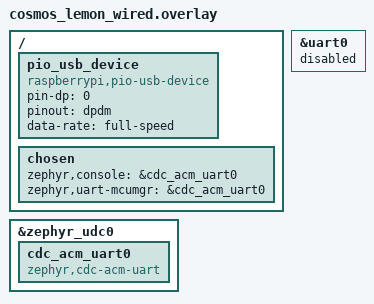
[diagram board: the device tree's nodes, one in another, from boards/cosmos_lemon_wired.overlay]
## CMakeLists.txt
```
# SPDX-License-Identifier: MIT

cmake_minimum_required(VERSION 3.20.0)
find_package(Zephyr REQUIRED HINTS $ENV{ZEPHYR_BASE})
project(pio_usb_device)

target_sources(app PRIVATE src/main.c)
```

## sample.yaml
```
sample:
  name: Pico-PIO-USB UDC standalone
  description: |
    Brings up udc_pio_usb on a Lemon Wired and exposes a CDC ACM device
    on the configured Link USB-C port. Pair with samples/pio_usb_host/
    on a second Lemon for an end-to-end test.
tests:
  sample.zephyr-module-pio-usb.device:
    platform_allow: cosmos_lemon_wired rpi_pico
    tags: usb pio
```

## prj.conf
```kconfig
# SPDX-License-Identifier: MIT
#
# Pico-PIO-USB device standalone sample. Brings up udc_pio_usb on a
# Lemon Wired and exposes a CDC ACM device on the configured Link
# USB-C port via Zephyr's USBD-next stack.
#
# Logs go out the native USB-C port via a separate CDC ACM instance.
# The CDC ACM that the Link port presents is the test endpoint — type
# in the host's tty and it should echo back.

CONFIG_MAIN_STACK_SIZE=2048

CONFIG_LOG=y
CONFIG_LOG_BUFFER_SIZE=8192
CONFIG_LOG_DEFAULT_LEVEL=3
CONFIG_LOG_PRINTK=y
CONFIG_LOG_MODE_IMMEDIATE=y
CONFIG_USB_DRIVER_LOG_LEVEL_INF=y
CONFIG_UDC_DRIVER_LOG_LEVEL_DBG=y
CONFIG_USB_DEVICE_LOG_LEVEL_INF=y

# udc_pio_usb on the Link USB-C port (PIO-driven).
CONFIG_UDC_DRIVER=y
CONFIG_UDC_PIO_USB=y
CONFIG_DYNAMIC_INTERRUPTS=y

# Legacy USB device stack on the native USB-C port for serial console
# only — no USBD-next on Link. Once udc_pio_usb is hardware-validated,
# add USBD-next + CDC ACM back to expose a real CDC ACM device on Link.
# Both stacks can't define CDC ACM concurrently (linker conflict on
# duplicated DT instance ordinals), so this triage build trades the
# Link-side test endpoint for a native serial console.
CONFIG_USB_DEVICE_STACK=y
CONFIG_USB_DEVICE_PRODUCT="Cosmos Lemon UDC Triage"
CONFIG_USB_DEVICE_PID=0x0004
CONFIG_USB_DEVICE_INITIALIZE_AT_BOOT=y
CONFIG_USB_CDC_ACM=y
CONFIG_SERIAL=y
CONFIG_UART_LINE_CTRL=y
CONFIG_UART_INTERRUPT_DRIVEN=y
CONFIG_CONSOLE=y
CONFIG_UART_CONSOLE=y
CONFIG_LOG_BACKEND_UART=y

# Skip flash and NVS — not needed for the smoke test.
CONFIG_FLASH=n
CONFIG_NVS=n
CONFIG_SETTINGS=n
```

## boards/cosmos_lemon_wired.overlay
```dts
/*
 * SPDX-License-Identifier: MIT
 *
 * Lemon Wired overlay for the UDC sample. The Link USB-C port (D+ on
 * GP0, D- on GP1) drives Pico-PIO-USB in device mode.
 *
 * &uart0 owns GP0/GP1 by default for the wired-split transport — we
 * disable it here so Pico-PIO-USB can take the pins. The board's
 * native USBD stays available but isn't used by this sample.
 */

&uart0 {
	status = "disabled";
};

/ {
	pio_usb_device: pio_usb_device {
		compatible = "raspberrypi,pio-usb-device";
		pin-dp = <0>;
		pinout = "dpdm";
		data-rate = "full-speed";
		status = "okay";
	};

	chosen {
		zephyr,console = &cdc_acm_uart0;
		zephyr,uart-mcumgr = &cdc_acm_uart0;
	};
};

/* Triage build: native USB-C exposes a CDC ACM serial console via the
 * legacy USB device stack (so we get logs out of the firmware). The
 * Link USB-C port runs udc_pio_usb but exposes no class — the
 * standalone-PIO-USB-init smoke test is sufficient until USBD-next +
 * CDC ACM dual-stack issues are resolved. */
&zephyr_udc0 {
	cdc_acm_uart0: cdc_acm_uart0 {
		compatible = "zephyr,cdc-acm-uart";
	};
};
```

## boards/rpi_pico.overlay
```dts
/*
 * SPDX-License-Identifier: MIT
 *
 * Raspberry Pi Pico overlay for the UDC sample. PIO-USB drives D+/D- on
 * GP0/GP1 in device mode (Pico-PIO-USB convention); the native USB
 * block stays on &zephyr_udc0 for the CDC ACM serial console.
 *
 * Wire D+ to GP0 and D- to GP1 — typically through a USB-C / USB-A
 * jack — and connect that jack to a host PC (or a second board running
 * the pio_usb_host sample).
 *
 * &uart0 owns GP0/GP1 by default — disable it here so PIO-USB can
 * take the pins.
 */

&uart0 {
	status = "disabled";
};

/ {
	pio_usb_device: pio_usb_device {
		compatible = "raspberrypi,pio-usb-device";
		pin-dp = <0>;
		pinout = "dpdm";
		data-rate = "full-speed";
		status = "okay";
	};

	chosen {
		zephyr,console = &cdc_acm_uart0;
		zephyr,uart-mcumgr = &cdc_acm_uart0;
	};
};

/* CDC ACM serial console exposed on the native USB-B port. */
&zephyr_udc0 {
	cdc_acm_uart0: cdc_acm_uart0 {
		compatible = "zephyr,cdc-acm-uart";
	};
};
```

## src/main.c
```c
/*
 * Copyright (c) 2026 The Cosmos-Keyboards Contributors
 *
 * SPDX-License-Identifier: MIT
 *
 * Pico-PIO-USB device standalone triage. Brings up udc_pio_usb on the
 * Link USB-C port and waits — no USBD-next class on top, just confirm
 * the driver init sequence reaches steady state without faulting and
 * the PIO-USB device-mode signaling holds D+ high so a host (or our
 * UHC sample on a second Lemon) sees the line in FS_IDLE.
 *
 * Logs go out the native USB-C port via legacy USBD CDC ACM. This
 * sample currently sacrifices the Link-side CDC ACM test endpoint to
 * keep the bring-up triage simple.
 */

#include <zephyr/device.h>
#include <zephyr/devicetree.h>
#include <zephyr/drivers/uart.h>
#include <zephyr/drivers/usb/udc.h>
#include <zephyr/init.h>
#include <zephyr/kernel.h>
#include <zephyr/logging/log.h>

LOG_MODULE_REGISTER(pio_usb_device_sample, LOG_LEVEL_DBG);

#define UDC_NODE DT_NODELABEL(pio_usb_device)
#define CONSOLE_NODE DT_CHOSEN(zephyr_console)

static const struct device *udc_dev = DEVICE_DT_GET(UDC_NODE);
static const struct device *console = DEVICE_DT_GET(CONSOLE_NODE);

static void wait_for_console(void)
{
	uint32_t dtr = 0;
	for (int i = 0; i < 30; i++) {
		printk("wfc i=%d dtr=%u\n", i, dtr);
		uart_line_ctrl_get(console, UART_LINE_CTRL_DTR, &dtr);
		if (dtr) {
			break;
		}
		k_msleep(100);
	}
	k_msleep(200);
}

static int udc_event(const struct device *dev,
		     const struct udc_event *const evt)
{
	ARG_UNUSED(dev);
	switch (evt->type) {
	case UDC_EVT_VBUS_READY:    LOG_INF("VBUS ready"); break;
	case UDC_EVT_VBUS_REMOVED:  LOG_INF("VBUS removed"); break;
	case UDC_EVT_RESET:         LOG_INF("Bus reset"); break;
	case UDC_EVT_SOF:           /* too noisy to log */ break;
	case UDC_EVT_SUSPEND:       LOG_INF("Bus suspend"); break;
	case UDC_EVT_RESUME:        LOG_INF("Bus resume"); break;
	case UDC_EVT_EP_REQUEST:    LOG_INF("EP request"); break;
	case UDC_EVT_ERROR:         LOG_WRN("Error"); break;
	default:                    LOG_DBG("UDC event %d", evt->type); break;
	}
	return 0;
}

int main(void)
{
	int ret;

	printk("\n*** UDC_MAIN_START ***\n");
	wait_for_console();
	printk("*** wait_for_console done ***\n");

	LOG_INF("Pico-PIO-USB device sample (triage) starting");

	if (!device_is_ready(udc_dev)) {
		LOG_ERR("UDC device %s not ready", udc_dev->name);
		return -ENODEV;
	}
	LOG_INF("UDC device %s present", udc_dev->name);

	ret = udc_init(udc_dev, udc_event);
	if (ret) {
		LOG_ERR("udc_init failed: %d", ret);
		return ret;
	}
	LOG_INF("udc_init OK");

	ret = udc_enable(udc_dev);
	if (ret) {
		LOG_ERR("udc_enable failed: %d", ret);
		return ret;
	}
	LOG_INF("UDC enabled — Link USB-C port should now signal as USB-FS device");

	uint32_t tick = 0;
	while (1) {
		LOG_INF("alive t=%us", tick * 2);
		tick++;
		k_msleep(2000);
	}
	return 0;
}
```
